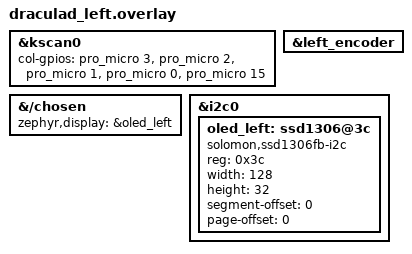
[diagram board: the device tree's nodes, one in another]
/* config/boards/shields/draculad/draculad_left.overlay */

#include "draculad.dtsi"

/* Matriz – confira se os pinos batem com o seu PCB */
&kscan0 {
    col-gpios = <&pro_micro 3  GPIO_ACTIVE_HIGH>,
                <&pro_micro 2  GPIO_ACTIVE_HIGH>,
                <&pro_micro 1  GPIO_ACTIVE_HIGH>,
                <&pro_micro 0  GPIO_ACTIVE_HIGH>,
                <&pro_micro 15 GPIO_ACTIVE_HIGH>;
};

/* Encoder do lado esquerdo (definido no .dtsi) */
&left_encoder {
    status = "okay";
};

/* Escolhe o display deste lado */
&{/chosen} {
    zephyr,display = &oled_left;
};

/* --- OLED no barramento I²C (troque &i2c0 por &i2c1 se o seu hardware usar i2c1) --- */
&i2c0 {
    status = "okay";

    oled_left: ssd1306@3c {
        compatible = "solomon,ssd1306fb-i2c";
        reg = <0x3c>;
        width = <128>;
        height = <32>;
        segment-offset = <0>;
        page-offset = <0>;
        status = "okay";
        /* Se houver pino RESET conectado, descomente e ajuste:
         * reset-gpios = <&gpio0 10 GPIO_ACTIVE_LOW>;
         */
        /* Opcional: velocidade do barramento
         * bus-speed = <I2C_BITRATE_FAST>;
         */
    };
};
